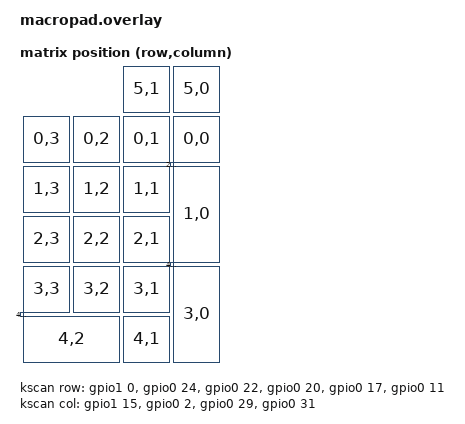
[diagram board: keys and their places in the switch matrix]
// This file was generated from a template. Edit it to match your keyboard.
// See https://zmk.dev/docs/development/hardware-integration/new-shield for more
// instructions.

#include <dt-bindings/zmk/matrix_transform.h>

#include "macropad-layouts.dtsi"

/ {
    chosen {
        zmk,physical-layout = &physical_layout;
        zmk,backlight = &backlight;
    };
    
    backlight: leds {
        compatible = "gpio-leds";
        blue_led: led_0 {
            gpios = <&gpio0 15 GPIO_ACTIVE_HIGH>;
        };
    };

    kscan: kscan {
        // If the hardware does not use a switch matrix, change this to the
        // appropriate driver and update the properties below to match.
        // See https://zmk.dev/docs/config/kscan for supported key scan drivers.
        compatible = "zmk,kscan-gpio-matrix";
        // Set this to "col2row" or "row2col" to match the hardware. If using
        // "row2col", change the col-gpios to (GPIO_ACTIVE_HIGH | GPIO_PULL_DOWN)
        // and the row-gpios to GPIO_ACTIVE_HIGH.
        diode-direction = "col2row";
        wakeup-source;

        // Replace these comments with the GPIO pins in the matrix.
        // See https://zmk.dev/docs/development/hardware-integration/new-shield#shield-overlays
        col-gpios
            = <&gpio1 15 GPIO_ACTIVE_HIGH> 
            , <&gpio0 2  GPIO_ACTIVE_HIGH> 
            , <&gpio0 29 GPIO_ACTIVE_HIGH> 
            , <&gpio0 31 GPIO_ACTIVE_HIGH> 
            ;

        row-gpios
            = <&gpio1 0 (GPIO_ACTIVE_HIGH | GPIO_PULL_DOWN)> 
            , <&gpio0 24 (GPIO_ACTIVE_HIGH | GPIO_PULL_DOWN)> 
            , <&gpio0 22 (GPIO_ACTIVE_HIGH | GPIO_PULL_DOWN)> 
            , <&gpio0 20 (GPIO_ACTIVE_HIGH | GPIO_PULL_DOWN)> 
            , <&gpio0 17 (GPIO_ACTIVE_HIGH | GPIO_PULL_DOWN)> 
            , <&gpio0 11 (GPIO_ACTIVE_HIGH | GPIO_PULL_DOWN)> 
            ;
    };

    default_transform: default_transform {
        // See https://zmk.dev/docs/development/hardware-integration/new-shield#matrix-transform
        // for how to configure this
        compatible = "zmk,matrix-transform";
        columns = <4>;
        rows = <6>;

        map = <           
            RC(0,0) RC(0,1) RC(0,2) RC(0,3)
            RC(1,0) RC(1,1) RC(1,2) RC(1,3)
            RC(2,0) RC(2,1) RC(2,2) RC(2,3)
            RC(3,0) RC(3,1) RC(3,2) RC(3,3)
            RC(4,0) RC(4,1) RC(4,2) RC(4,3)
            RC(5,0) RC(5,1)
        >;
    };

    physical_layout: physical_layout {
    compatible = "zmk,physical-layout";
    display-name = "Default Layout";
    kscan = <&kscan>;
    transform = <&default_transform>;
    //                          w    h      x    y       rot    rx    ry
    keys 
        = <&key_physical_attrs 100  100    300  100      0     0     0> // 0: -
        , <&key_physical_attrs 100  100    200  100      0     0     0> // 1: *
        , <&key_physical_attrs 100  100    100  100      0     0     0> // 2: /
        , <&key_physical_attrs 100  100    0    100      0     0     0> // 3: BSPC
        
        , <&key_physical_attrs 100  200    300  200      0     0     0> // 4: + (2U High)
        , <&key_physical_attrs 100  100    200  200      0     0     0> // 5: 9
        , <&key_physical_attrs 100  100    100  200      0     0     0> // 6: 8
        , <&key_physical_attrs 100  100      0  200      0     0     0> // 7: 7
        
        , <&key_physical_attrs 1  1    300  200      0     0     0> // 8: Dummy +
        , <&key_physical_attrs 100  100    200  300      0     0     0> // 9: 6
        , <&key_physical_attrs 100  100    100  300      0     0     0> // 10: 5
        , <&key_physical_attrs 100  100      0  300      0     0     0> // 11: 4
        
        , <&key_physical_attrs 100  200    300  400      0     0     0> // 12: Enter (2U High)
        , <&key_physical_attrs 100  100    200  400      0     0     0> // 13: 3
        , <&key_physical_attrs 100  100    100  400      0     0     0> // 14: 2
        , <&key_physical_attrs 100  100      0  400      0     0     0> // 15: 1
        
        , <&key_physical_attrs 1  1    300  400      0     0     0> // 16: Dummy Enter
        , <&key_physical_attrs 100  100    200  500      0     0     0> // 17: .
        , <&key_physical_attrs 200  100      0  500      0     0     0> // 18: 0 (2U Wide)
        , <&key_physical_attrs 1  1      0  500      0     0     0> // 19: Dummy 0
        
        , <&key_physical_attrs 100  100    300    0      0     0     0> // 20: TOG 1
        , <&key_physical_attrs 100  100    200    0      0     0     0> // 21: ESC
        ;
    };
};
